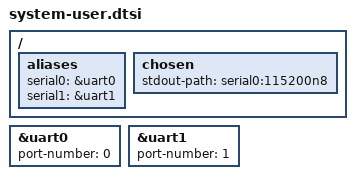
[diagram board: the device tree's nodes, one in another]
/include/ "system-conf.dtsi"
/ {
};

/* 2025.2 gen-machineconf assigns port-number=0 to uart1, making ttyPS0 map
 * to uart1. Vitis bsp.yaml confirms this board uses psu_uart_0, so force
 * ttyPS0 back to uart0. */
&uart0 {
   port-number = <0>;
};
&uart1 {
   port-number = <1>;
};
/ {
   aliases {
      serial0 = &uart0;
      serial1 = &uart1;
   };
   chosen {
      stdout-path = "serial0:115200n8";
   };
};
